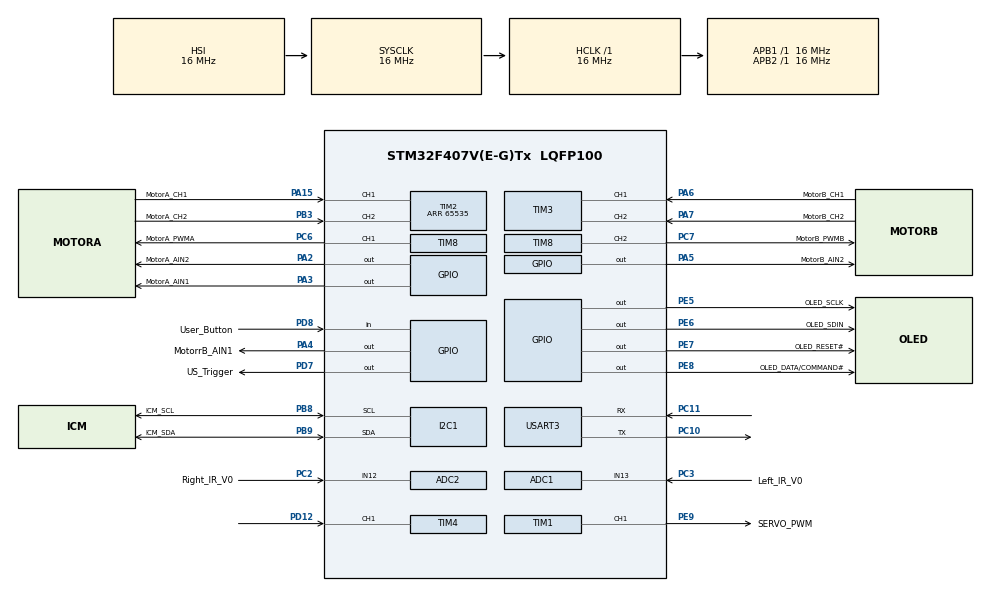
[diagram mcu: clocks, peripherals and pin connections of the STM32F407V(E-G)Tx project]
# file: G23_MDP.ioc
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ADC1.Channel-0\#ChannelRegularConversion=ADC_CHANNEL_13
ADC1.ContinuousConvMode=ENABLE
ADC1.NbrOfConversion=1
ADC1.NbrOfConversionFlag=1
ADC1.Rank-0\#ChannelRegularConversion=1
ADC1.Resolution=ADC_RESOLUTION_12B
ADC1.SamplingTime-0\#ChannelRegularConversion=ADC_SAMPLETIME_3CYCLES
ADC1.ScanConvMode=DISABLE
ADC1.master=1
ADC2.Channel-1\#ChannelRegularConversion=ADC_CHANNEL_12
ADC2.NbrOfConversionFlag=1
ADC2.Rank-1\#ChannelRegularConversion=1
ADC2.SamplingTime-1\#ChannelRegularConversion=ADC_SAMPLETIME_3CYCLES
I2C1.I2C_Mode=I2C_Fast
I2C1.NoStretchMode=I2C_NOSTRETCH_DISABLE
Mcu.Family=STM32F4
Mcu.Name=STM32F407V(E-G)Tx
Mcu.Package=LQFP100
NVIC.ADC_IRQn=true\:0\:0\:false\:false\:true\:true\:true\:true
NVIC.PriorityGroup=NVIC_PRIORITYGROUP_4
NVIC.TIM1_CC_IRQn=true\:0\:0\:false\:false\:true\:true\:true\:true
NVIC.TIM4_IRQn=true\:0\:0\:false\:false\:true\:true\:true\:true
NVIC.TIM7_IRQn=true\:0\:0\:false\:false\:true\:true\:true\:true
NVIC.USART3_IRQn=true\:0\:0\:false\:false\:true\:true\:true\:true
PA13.Signal=SYS_JTMS-SWDIO
PA14.Signal=SYS_JTCK-SWCLK
PA15.GPIO_Label=MotorA_CH1
PA15.Signal=S_TIM2_CH1_ETR
PA2.GPIO_Label=MotorA_AIN2
PA2.Signal=GPIO_Output
PA3.GPIO_Label=MotorA_AIN1
PA3.Signal=GPIO_Output
PA4.GPIO_Label=MotorrB_AIN1
PA4.Signal=GPIO_Output
PA5.GPIO_Label=MotorB_AIN2
PA5.Signal=GPIO_Output
PA6.GPIO_Label=MotorB_CH1
PA6.Signal=S_TIM3_CH1
PA7.GPIO_Label=MotorB_CH2
PA7.Signal=S_TIM3_CH2
PB3.GPIO_Label=MotorA_CH2
PB3.Signal=S_TIM2_CH2
PB8.GPIO_Label=ICM_SCL
PB8.Mode=I2C
PB8.Signal=I2C1_SCL
PB9.GPIO_Label=ICM_SDA
PB9.Mode=I2C
PB9.Signal=I2C1_SDA
PC10.Mode=Asynchronous
PC10.Signal=USART3_TX
PC11.Mode=Asynchronous
PC11.Signal=USART3_RX
PC2.GPIO_Label=Right_IR_V0
PC2.Signal=ADCx_IN12
PC3.GPIO_Label=Left_IR_V0
PC3.Signal=ADCx_IN13
PC6.GPIO_Label=MotorA_PWMA
PC6.Signal=S_TIM8_CH1
PC7.GPIO_Label=MotorB_PWMB
PC7.Signal=S_TIM8_CH2
PD12.Signal=S_TIM4_CH1
PD7.GPIO_Label=US_Trigger
PD7.Signal=GPIO_Output
PD8.GPIO_Label=User_Button
PD8.GPIO_PuPd=GPIO_PULLUP
PD8.Signal=GPIO_Input
PE5.GPIO_Label=OLED_SCLK
PE5.Signal=GPIO_Output
PE6.GPIO_Label=OLED_SDIN
PE6.Signal=GPIO_Output
PE7.GPIO_Label=OLED_RESET\#
PE7.Signal=GPIO_Output
PE8.GPIO_Label=OLED_DATA/COMMAND\#
PE8.Signal=GPIO_Output
PE9.GPIO_Label=SERVO_PWM
PE9.Signal=S_TIM1_CH1
ProjectManager.HeapSize=0x200
ProjectManager.StackSize=0x400
ProjectManager.TargetToolchain=STM32CubeIDE
RCC.AHBFreq_Value=16000000
RCC.APB1Freq_Value=16000000
RCC.APB2Freq_Value=16000000
RCC.APB2TimFreq_Value=16000000
RCC.CortexFreq_Value=16000000
RCC.HSE_VALUE=25000000
RCC.HSI_VALUE=16000000
RCC.LSE_VALUE=32768
RCC.SYSCLKFreq_VALUE=16000000
RCC.VCOOutputFreq_Value=192000000
SH.ADCx_IN12.0=ADC2_IN12,IN12
SH.ADCx_IN13.0=ADC1_IN13,IN13
SH.S_TIM1_CH1.0=TIM1_CH1,PWM Generation1 CH1
SH.S_TIM2_CH1_ETR.0=TIM2_CH1,Encoder_Interface
SH.S_TIM2_CH2.0=TIM2_CH2,Encoder_Interface
SH.S_TIM3_CH1.0=TIM3_CH1,Encoder_Interface
SH.S_TIM3_CH2.0=TIM3_CH2,Encoder_Interface
SH.S_TIM4_CH1.0=TIM4_CH1,Input_Capture1_from_TI1
SH.S_TIM8_CH1.0=TIM8_CH1,PWM Generation1 CH1
SH.S_TIM8_CH2.0=TIM8_CH2,PWM Generation2 CH2
TIM1.Channel-PWM\ Generation1\ CH1=TIM_CHANNEL_1
TIM1.CounterMode=TIM_COUNTERMODE_UP
TIM1.OCMode_PWM-PWM\ Generation1\ CH1=TIM_OCMODE_PWM1
TIM1.Period=64000-1
TIM1.Prescaler=5-1
TIM2.EncoderMode=TIM_ENCODERMODE_TI12
TIM2.IC1Polarity=TIM_ICPOLARITY_RISING
TIM2.IC2Polarity=TIM_ICPOLARITY_RISING
TIM2.Period=65535
TIM3.EncoderMode=TIM_ENCODERMODE_TI12
TIM3.IC1Filter=0
TIM3.IC1Polarity=TIM_ICPOLARITY_RISING
TIM3.IC2Filter=0
TIM3.IC2Polarity=TIM_ICPOLARITY_RISING
TIM4.Channel-Input_Capture1_from_TI1=TIM_CHANNEL_1
TIM4.Period=65536-1
TIM4.Prescaler=16-1
TIM6.Period=65536-1
TIM6.Prescaler=16-1
TIM7.Period=16000-1
TIM7.Prescaler=2-1
TIM8.Channel-PWM\ Generation1\ CH1=TIM_CHANNEL_1
TIM8.Channel-PWM\ Generation2\ CH2=TIM_CHANNEL_2
TIM8.Period=7200-1
USART3.VirtualMode=VM_ASYNC
VP_TIM1_VS_ClockSourceINT.Mode=Internal
VP_TIM4_VS_ClockSourceINT.Mode=Internal
VP_TIM6_VS_ClockSourceINT.Mode=Enable_Timer
VP_TIM7_VS_ClockSourceINT.Mode=Enable_Timer
VP_TIM8_VS_ClockSourceINT.Mode=Internal
board=custom

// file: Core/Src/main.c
/* USER CODE BEGIN Header */
/**
  ******************************************************************************
  * @file           : main.c
  * @brief          : Main program body
  ******************************************************************************
  * @attention
  *
  * Copyright (c) 2024 STMicroelectronics.
  * All rights reserved.
  *
  * This software is licensed under terms that can be found in the LICENSE file
  * in the root directory of this software component.
  * If no LICENSE file comes with this software, it is provided AS-IS.
  *
  ******************************************************************************
  */
/* USER CODE END Header */
#include <userbutton.h>
#include "main.h"

/* USER CODE BEGIN Includes */
#include "oled.h"
#include "userbutton.h"
#include "servomotor.h"
#include "sensorstuff.h"

/* USER CODE END Includes */

ADC_HandleTypeDef hadc1;
ADC_HandleTypeDef hadc2;

I2C_HandleTypeDef hi2c1;

TIM_HandleTypeDef htim1;
TIM_HandleTypeDef htim2;
TIM_HandleTypeDef htim3;
TIM_HandleTypeDef htim4;
TIM_HandleTypeDef htim6;
TIM_HandleTypeDef htim7;
TIM_HandleTypeDef htim8;

UART_HandleTypeDef huart3;

void SystemClock_Config(void);
static void MX_GPIO_Init(void);
static void MX_USART3_UART_Init(void);
static void MX_I2C1_Init(void);
static void MX_TIM8_Init(void);
static void MX_TIM2_Init(void);
static void MX_TIM3_Init(void);
static void MX_TIM1_Init(void);
static void MX_TIM4_Init(void);
static void MX_ADC1_Init(void);
static void MX_TIM6_Init(void);
static void MX_TIM7_Init(void);
static void MX_ADC2_Init(void);

int main(void)
{

  /* MCU Configuration--------------------------------------------------------*/

  /* Reset of all peripherals, Initializes the Flash interface and the Systick. */
  HAL_Init();

  /* USER CODE BEGIN Init */
  OLED_Init();
  /* USER CODE END Init */

  /* Configure the system clock */
  SystemClock_Config();

  /* Initialize all configured peripherals */
  MX_GPIO_Init();
  MX_USART3_UART_Init();
  MX_I2C1_Init();
  MX_TIM8_Init();
  MX_TIM2_Init();
  MX_TIM3_Init();
  MX_TIM1_Init();
  MX_TIM4_Init();
  MX_ADC1_Init();
  MX_TIM6_Init();
  MX_TIM7_Init();
  MX_ADC2_Init();

  /* Infinite loop */
  while (1)
  {

  }
}

void SystemClock_Config(void)
{
  RCC_OscInitTypeDef RCC_OscInitStruct = {0};
  RCC_ClkInitTypeDef RCC_ClkInitStruct = {0};

  /** Configure the main internal regulator output voltage
  */
  __HAL_RCC_PWR_CLK_ENABLE();
  __HAL_PWR_VOLTAGESCALING_CONFIG(PWR_REGULATOR_VOLTAGE_SCALE1);

  /** Initializes the RCC Oscillators according to the specified parameters
  * in the RCC_OscInitTypeDef structure.
  */
  RCC_OscInitStruct.OscillatorType = RCC_OSCILLATORTYPE_HSI;
  RCC_OscInitStruct.HSIState = RCC_HSI_ON;
  RCC_OscInitStruct.HSICalibrationValue = RCC_HSICALIBRATION_DEFAULT;
  RCC_OscInitStruct.PLL.PLLState = RCC_PLL_NONE;
  if (HAL_RCC_OscConfig(&RCC_OscInitStruct) != HAL_OK)
  {
    Error_Handler();
  }

  /** Initializes the CPU, AHB and APB buses clocks
  */
  RCC_ClkInitStruct.ClockType = RCC_CLOCKTYPE_HCLK|RCC_CLOCKTYPE_SYSCLK
                              |RCC_CLOCKTYPE_PCLK1|RCC_CLOCKTYPE_PCLK2;
  RCC_ClkInitStruct.SYSCLKSource = RCC_SYSCLKSOURCE_HSI;
  RCC_ClkInitStruct.AHBCLKDivider = RCC_SYSCLK_DIV1;
  RCC_ClkInitStruct.APB1CLKDivider = RCC_HCLK_DIV1;
  RCC_ClkInitStruct.APB2CLKDivider = RCC_HCLK_DIV1;

  if (HAL_RCC_ClockConfig(&RCC_ClkInitStruct, FLASH_LATENCY_0) != HAL_OK)
  {
    Error_Handler();
  }
}

static void MX_ADC1_Init(void)
{

  ADC_ChannelConfTypeDef sConfig = {0};

  /** Configure the global features of the ADC (Clock, Resolution, Data Alignment and number of conversion)
  */
  hadc1.Instance = ADC1;
  hadc1.Init.ClockPrescaler = ADC_CLOCK_SYNC_PCLK_DIV2;
  hadc1.Init.Resolution = ADC_RESOLUTION_12B;
  hadc1.Init.ScanConvMode = DISABLE;
  hadc1.Init.ContinuousConvMode = ENABLE;
  hadc1.Init.DiscontinuousConvMode = DISABLE;
  hadc1.Init.ExternalTrigConvEdge = ADC_EXTERNALTRIGCONVEDGE_NONE;
  hadc1.Init.ExternalTrigConv = ADC_SOFTWARE_START;
  hadc1.Init.DataAlign = ADC_DATAALIGN_RIGHT;
  hadc1.Init.NbrOfConversion = 1;
  hadc1.Init.DMAContinuousRequests = DISABLE;
  hadc1.Init.EOCSelection = ADC_EOC_SINGLE_CONV;
  if (HAL_ADC_Init(&hadc1) != HAL_OK)
  {
    Error_Handler();
  }

  /** Configure for the selected ADC regular channel its corresponding rank in the sequencer and its sample time.
  */
  sConfig.Channel = ADC_CHANNEL_13;
  sConfig.Rank = 1;
  sConfig.SamplingTime = ADC_SAMPLETIME_3CYCLES;
  if (HAL_ADC_ConfigChannel(&hadc1, &sConfig) != HAL_OK)
  {
    Error_Handler();
  }

}

static void MX_ADC2_Init(void)
{

  ADC_ChannelConfTypeDef sConfig = {0};

  /** Configure the global features of the ADC (Clock, Resolution, Data Alignment and number of conversion)
  */
  hadc2.Instance = ADC2;
  hadc2.Init.ClockPrescaler = ADC_CLOCK_SYNC_PCLK_DIV2;
  hadc2.Init.Resolution = ADC_RESOLUTION_12B;
  hadc2.Init.ScanConvMode = DISABLE;
  hadc2.Init.ContinuousConvMode = DISABLE;
  hadc2.Init.DiscontinuousConvMode = DISABLE;
  hadc2.Init.ExternalTrigConvEdge = ADC_EXTERNALTRIGCONVEDGE_NONE;
  hadc2.Init.ExternalTrigConv = ADC_SOFTWARE_START;
  hadc2.Init.DataAlign = ADC_DATAALIGN_RIGHT;
  hadc2.Init.NbrOfConversion = 1;
  hadc2.Init.DMAContinuousRequests = DISABLE;
  hadc2.Init.EOCSelection = ADC_EOC_SINGLE_CONV;
  if (HAL_ADC_Init(&hadc2) != HAL_OK)
  {
    Error_Handler();
  }

  /** Configure for the selected ADC regular channel its corresponding rank in the sequencer and its sample time.
  */
  sConfig.Channel = ADC_CHANNEL_12;
  sConfig.Rank = 1;
  sConfig.SamplingTime = ADC_SAMPLETIME_3CYCLES;
  if (HAL_ADC_ConfigChannel(&hadc2, &sConfig) != HAL_OK)
  {
    Error_Handler();
  }

}

static void MX_I2C1_Init(void)
{

  hi2c1.Instance = I2C1;
  hi2c1.Init.ClockSpeed = 400000;
  hi2c1.Init.DutyCycle = I2C_DUTYCYCLE_2;
  hi2c1.Init.OwnAddress1 = 0;
  hi2c1.Init.AddressingMode = I2C_ADDRESSINGMODE_7BIT;
  hi2c1.Init.DualAddressMode = I2C_DUALADDRESS_DISABLE;
  hi2c1.Init.OwnAddress2 = 0;
  hi2c1.Init.GeneralCallMode = I2C_GENERALCALL_DISABLE;
  hi2c1.Init.NoStretchMode = I2C_NOSTRETCH_DISABLE;
  if (HAL_I2C_Init(&hi2c1) != HAL_OK)
  {
    Error_Handler();
  }

}

static void MX_TIM1_Init(void)
{

  TIM_ClockConfigTypeDef sClockSourceConfig = {0};
  TIM_MasterConfigTypeDef sMasterConfig = {0};
  TIM_OC_InitTypeDef sConfigOC = {0};
  TIM_BreakDeadTimeConfigTypeDef sBreakDeadTimeConfig = {0};

  htim1.Instance = TIM1;
  htim1.Init.Prescaler = 5-1;
  htim1.Init.CounterMode = TIM_COUNTERMODE_UP;
  htim1.Init.Period = 64000-1;
  htim1.Init.ClockDivision = TIM_CLOCKDIVISION_DIV1;
  htim1.Init.RepetitionCounter = 0;
  htim1.Init.AutoReloadPreload = TIM_AUTORELOAD_PRELOAD_DISABLE;
  if (HAL_TIM_Base_Init(&htim1) != HAL_OK)
  {
    Error_Handler();
  }
  sClockSourceConfig.ClockSource = TIM_CLOCKSOURCE_INTERNAL;
  if (HAL_TIM_ConfigClockSource(&htim1, &sClockSourceConfig) != HAL_OK)
  {
    Error_Handler();
  }
  if (HAL_TIM_PWM_Init(&htim1) != HAL_OK)
  {
    Error_Handler();
  }
  sMasterConfig.MasterOutputTrigger = TIM_TRGO_RESET;
  sMasterConfig.MasterSlaveMode = TIM_MASTERSLAVEMODE_DISABLE;
  if (HAL_TIMEx_MasterConfigSynchronization(&htim1, &sMasterConfig) != HAL_OK)
  {
    Error_Handler();
  }
  sConfigOC.OCMode = TIM_OCMODE_PWM1;
  sConfigOC.Pulse = 0;
  sConfigOC.OCPolarity = TIM_OCPOLARITY_HIGH;
  sConfigOC.OCNPolarity = TIM_OCNPOLARITY_HIGH;
  sConfigOC.OCFastMode = TIM_OCFAST_DISABLE;
  sConfigOC.OCIdleState = TIM_OCIDLESTATE_RESET;
  sConfigOC.OCNIdleState = TIM_OCNIDLESTATE_RESET;
  if (HAL_TIM_PWM_ConfigChannel(&htim1, &sConfigOC, TIM_CHANNEL_1) != HAL_OK)
  {
    Error_Handler();
  }
  sBreakDeadTimeConfig.OffStateRunMode = TIM_OSSR_DISABLE;
  sBreakDeadTimeConfig.OffStateIDLEMode = TIM_OSSI_DISABLE;
  sBreakDeadTimeConfig.LockLevel = TIM_LOCKLEVEL_OFF;
  sBreakDeadTimeConfig.DeadTime = 0;
  sBreakDeadTimeConfig.BreakState = TIM_BREAK_DISABLE;
  sBreakDeadTimeConfig.BreakPolarity = TIM_BREAKPOLARITY_HIGH;
  sBreakDeadTimeConfig.AutomaticOutput = TIM_AUTOMATICOUTPUT_DISABLE;
  if (HAL_TIMEx_ConfigBreakDeadTime(&htim1, &sBreakDeadTimeConfig) != HAL_OK)
  {
    Error_Handler();
  }
  HAL_TIM_MspPostInit(&htim1);

}

static void MX_TIM2_Init(void)
{

  TIM_Encoder_InitTypeDef sConfig = {0};
  TIM_MasterConfigTypeDef sMasterConfig = {0};

  htim2.Instance = TIM2;
  htim2.Init.Prescaler = 0;
  htim2.Init.CounterMode = TIM_COUNTERMODE_UP;
  htim2.Init.Period = 65535;
  htim2.Init.ClockDivision = TIM_CLOCKDIVISION_DIV1;
  htim2.Init.AutoReloadPreload = TIM_AUTORELOAD_PRELOAD_DISABLE;
  sConfig.EncoderMode = TIM_ENCODERMODE_TI12;
  sConfig.IC1Polarity = TIM_ICPOLARITY_RISING;
  sConfig.IC1Selection = TIM_ICSELECTION_DIRECTTI;
  sConfig.IC1Prescaler = TIM_ICPSC_DIV1;
  sConfig.IC1Filter = 0;
  sConfig.IC2Polarity = TIM_ICPOLARITY_RISING;
  sConfig.IC2Selection = TIM_ICSELECTION_DIRECTTI;
  sConfig.IC2Prescaler = TIM_ICPSC_DIV1;
  sConfig.IC2Filter = 0;
  if (HAL_TIM_Encoder_Init(&htim2, &sConfig) != HAL_OK)
  {
    Error_Handler();
  }
  sMasterConfig.MasterOutputTrigger = TIM_TRGO_RESET;
  sMasterConfig.MasterSlaveMode = TIM_MASTERSLAVEMODE_DISABLE;
  if (HAL_TIMEx_MasterConfigSynchronization(&htim2, &sMasterConfig) != HAL_OK)
  {
    Error_Handler();
  }

}

static void MX_TIM3_Init(void)
{

  TIM_Encoder_InitTypeDef sConfig = {0};
  TIM_MasterConfigTypeDef sMasterConfig = {0};

  htim3.Instance = TIM3;
  htim3.Init.Prescaler = 0;
  htim3.Init.CounterMode = TIM_COUNTERMODE_UP;
  htim3.Init.Period = 65535;
  htim3.Init.ClockDivision = TIM_CLOCKDIVISION_DIV1;
  htim3.Init.AutoReloadPreload = TIM_AUTORELOAD_PRELOAD_DISABLE;
  sConfig.EncoderMode = TIM_ENCODERMODE_TI12;
  sConfig.IC1Polarity = TIM_ICPOLARITY_RISING;
  sConfig.IC1Selection = TIM_ICSELECTION_DIRECTTI;
  sConfig.IC1Prescaler = TIM_ICPSC_DIV1;
  sConfig.IC1Filter = 0;
  sConfig.IC2Polarity = TIM_ICPOLARITY_RISING;
  sConfig.IC2Selection = TIM_ICSELECTION_DIRECTTI;
  sConfig.IC2Prescaler = TIM_ICPSC_DIV1;
  sConfig.IC2Filter = 0;
  if (HAL_TIM_Encoder_Init(&htim3, &sConfig) != HAL_OK)
  {
    Error_Handler();
  }
  sMasterConfig.MasterOutputTrigger = TIM_TRGO_RESET;
  sMasterConfig.MasterSlaveMode = TIM_MASTERSLAVEMODE_DISABLE;
  if (HAL_TIMEx_MasterConfigSynchronization(&htim3, &sMasterConfig) != HAL_OK)
  {
    Error_Handler();
  }

}

static void MX_TIM4_Init(void)
{

  TIM_ClockConfigTypeDef sClockSourceConfig = {0};
  TIM_MasterConfigTypeDef sMasterConfig = {0};
  TIM_IC_InitTypeDef sConfigIC = {0};

  htim4.Instance = TIM4;
  htim4.Init.Prescaler = 16-1;
  htim4.Init.CounterMode = TIM_COUNTERMODE_UP;
  htim4.Init.Period = 65536-1;
  htim4.Init.ClockDivision = TIM_CLOCKDIVISION_DIV1;
  htim4.Init.AutoReloadPreload = TIM_AUTORELOAD_PRELOAD_DISABLE;
  if (HAL_TIM_Base_Init(&htim4) != HAL_OK)
  {
    Error_Handler();
  }
  sClockSourceConfig.ClockSource = TIM_CLOCKSOURCE_INTERNAL;
  if (HAL_TIM_ConfigClockSource(&htim4, &sClockSourceConfig) != HAL_OK)
  {
    Error_Handler();
  }
  if (HAL_TIM_IC_Init(&htim4) != HAL_OK)
  {
    Error_Handler();
  }
  sMasterConfig.MasterOutputTrigger = TIM_TRGO_RESET;
  sMasterConfig.MasterSlaveMode = TIM_MASTERSLAVEMODE_DISABLE;
  if (HAL_TIMEx_MasterConfigSynchronization(&htim4, &sMasterConfig) != HAL_OK)
  {
    Error_Handler();
  }
  sConfigIC.ICPolarity = TIM_INPUTCHANNELPOLARITY_RISING;
  sConfigIC.ICSelection = TIM_ICSELECTION_DIRECTTI;
  sConfigIC.ICPrescaler = TIM_ICPSC_DIV1;
  sConfigIC.ICFilter = 0;
  if (HAL_TIM_IC_ConfigChannel(&htim4, &sConfigIC, TIM_CHANNEL_1) != HAL_OK)
  {
    Error_Handler();
  }

}

static void MX_TIM6_Init(void)
{

  TIM_MasterConfigTypeDef sMasterConfig = {0};

  htim6.Instance = TIM6;
  htim6.Init.Prescaler = 16-1;
  htim6.Init.CounterMode = TIM_COUNTERMODE_UP;
  htim6.Init.Period = 65536-1;
  htim6.Init.AutoReloadPreload = TIM_AUTORELOAD_PRELOAD_DISABLE;
  if (HAL_TIM_Base_Init(&htim6) != HAL_OK)
  {
    Error_Handler();
  }
  sMasterConfig.MasterOutputTrigger = TIM_TRGO_RESET;
  sMasterConfig.MasterSlaveMode = TIM_MASTERSLAVEMODE_DISABLE;
  if (HAL_TIMEx_MasterConfigSynchronization(&htim6, &sMasterConfig) != HAL_OK)
  {
    Error_Handler();
  }

}

static void MX_TIM7_Init(void)
{

  TIM_MasterConfigTypeDef sMasterConfig = {0};

  htim7.Instance = TIM7;
  htim7.Init.Prescaler = 2-1;
  htim7.Init.CounterMode = TIM_COUNTERMODE_UP;
  htim7.Init.Period = 16000-1;
  htim7.Init.AutoReloadPreload = TIM_AUTORELOAD_PRELOAD_DISABLE;
  if (HAL_TIM_Base_Init(&htim7) != HAL_OK)
  {
    Error_Handler();
  }
  sMasterConfig.MasterOutputTrigger = TIM_TRGO_RESET;
  sMasterConfig.MasterSlaveMode = TIM_MASTERSLAVEMODE_DISABLE;
  if (HAL_TIMEx_MasterConfigSynchronization(&htim7, &sMasterConfig) != HAL_OK)
  {
    Error_Handler();
  }

}

static void MX_TIM8_Init(void)
{

  TIM_ClockConfigTypeDef sClockSourceConfig = {0};
  TIM_MasterConfigTypeDef sMasterConfig = {0};
  TIM_OC_InitTypeDef sConfigOC = {0};
  TIM_BreakDeadTimeConfigTypeDef sBreakDeadTimeConfig = {0};

  htim8.Instance = TIM8;
  htim8.Init.Prescaler = 0;
  htim8.Init.CounterMode = TIM_COUNTERMODE_UP;
  htim8.Init.Period = 7200-1;
  htim8.Init.ClockDivision = TIM_CLOCKDIVISION_DIV1;
  htim8.Init.RepetitionCounter = 0;
  htim8.Init.AutoReloadPreload = TIM_AUTORELOAD_PRELOAD_DISABLE;
  if (HAL_TIM_Base_Init(&htim8) != HAL_OK)
  {
    Error_Handler();
  }
  sClockSourceConfig.ClockSource = TIM_CLOCKSOURCE_INTERNAL;
  if (HAL_TIM_ConfigClockSource(&htim8, &sClockSourceConfig) != HAL_OK)
  {
    Error_Handler();
  }
  if (HAL_TIM_PWM_Init(&htim8) != HAL_OK)
  {
    Error_Handler();
  }
  sMasterConfig.MasterOutputTrigger = TIM_TRGO_RESET;
  sMasterConfig.MasterSlaveMode = TIM_MASTERSLAVEMODE_DISABLE;
  if (HAL_TIMEx_MasterConfigSynchronization(&htim8, &sMasterConfig) != HAL_OK)
  {
    Error_Handler();
  }
  sConfigOC.OCMode = TIM_OCMODE_PWM1;
  sConfigOC.Pulse = 0;
  sConfigOC.OCPolarity = TIM_OCPOLARITY_HIGH;
  sConfigOC.OCNPolarity = TIM_OCNPOLARITY_HIGH;
  sConfigOC.OCFastMode = TIM_OCFAST_DISABLE;
  sConfigOC.OCIdleState = TIM_OCIDLESTATE_RESET;
  sConfigOC.OCNIdleState = TIM_OCNIDLESTATE_RESET;
  if (HAL_TIM_PWM_ConfigChannel(&htim8, &sConfigOC, TIM_CHANNEL_1) != HAL_OK)
  {
    Error_Handler();
  }
  if (HAL_TIM_PWM_ConfigChannel(&htim8, &sConfigOC, TIM_CHANNEL_2) != HAL_OK)
  {
    Error_Handler();
  }
  sBreakDeadTimeConfig.OffStateRunMode = TIM_OSSR_DISABLE;
  sBreakDeadTimeConfig.OffStateIDLEMode = TIM_OSSI_DISABLE;
  sBreakDeadTimeConfig.LockLevel = TIM_LOCKLEVEL_OFF;
  sBreakDeadTimeConfig.DeadTime = 0;
  sBreakDeadTimeConfig.BreakState = TIM_BREAK_DISABLE;
  sBreakDeadTimeConfig.BreakPolarity = TIM_BREAKPOLARITY_HIGH;
  sBreakDeadTimeConfig.AutomaticOutput = TIM_AUTOMATICOUTPUT_DISABLE;
  if (HAL_TIMEx_ConfigBreakDeadTime(&htim8, &sBreakDeadTimeConfig) != HAL_OK)
  {
    Error_Handler();
  }
  HAL_TIM_MspPostInit(&htim8);

}

static void MX_USART3_UART_Init(void)
{

  huart3.Instance = USART3;
  huart3.Init.BaudRate = 115200;
  huart3.Init.WordLength = UART_WORDLENGTH_8B;
  huart3.Init.StopBits = UART_STOPBITS_1;
  huart3.Init.Parity = UART_PARITY_NONE;
  huart3.Init.Mode = UART_MODE_TX_RX;
  huart3.Init.HwFlowCtl = UART_HWCONTROL_NONE;
  huart3.Init.OverSampling = UART_OVERSAMPLING_16;
  if (HAL_UART_Init(&huart3) != HAL_OK)
  {
    Error_Handler();
  }

}

static void MX_GPIO_Init(void)
{
  GPIO_InitTypeDef GPIO_InitStruct = {0};

  /* GPIO Ports Clock Enable */
  __HAL_RCC_GPIOE_CLK_ENABLE();
  __HAL_RCC_GPIOC_CLK_ENABLE();
  __HAL_RCC_GPIOA_CLK_ENABLE();
  __HAL_RCC_GPIOD_CLK_ENABLE();
  __HAL_RCC_GPIOB_CLK_ENABLE();

  /*Configure GPIO pin Output Level */
  HAL_GPIO_WritePin(GPIOE, OLED_SCLK_Pin|OLED_SDIN_Pin|OLED_RESET__Pin|OLED_DATA_COMMAND__Pin, GPIO_PIN_RESET);

  /*Configure GPIO pin Output Level */
  HAL_GPIO_WritePin(GPIOA, MotorA_AIN2_Pin|MotorA_AIN1_Pin|MotorrB_AIN1_Pin|MotorB_AIN2_Pin, GPIO_PIN_RESET);

  /*Configure GPIO pin Output Level */
  HAL_GPIO_WritePin(US_Trigger_GPIO_Port, US_Trigger_Pin, GPIO_PIN_RESET);

  /*Configure GPIO pins : OLED_SCLK_Pin OLED_SDIN_Pin OLED_RESET__Pin OLED_DATA_COMMAND__Pin */
  GPIO_InitStruct.Pin = OLED_SCLK_Pin|OLED_SDIN_Pin|OLED_RESET__Pin|OLED_DATA_COMMAND__Pin;
  GPIO_InitStruct.Mode = GPIO_MODE_OUTPUT_PP;
  GPIO_InitStruct.Pull = GPIO_NOPULL;
  GPIO_InitStruct.Speed = GPIO_SPEED_FREQ_LOW;
  HAL_GPIO_Init(GPIOE, &GPIO_InitStruct);

  /*Configure GPIO pins : MotorA_AIN2_Pin MotorA_AIN1_Pin MotorrB_AIN1_Pin MotorB_AIN2_Pin */
  GPIO_InitStruct.Pin = MotorA_AIN2_Pin|MotorA_AIN1_Pin|MotorrB_AIN1_Pin|MotorB_AIN2_Pin;
  GPIO_InitStruct.Mode = GPIO_MODE_OUTPUT_PP;
  GPIO_InitStruct.Pull = GPIO_NOPULL;
  GPIO_InitStruct.Speed = GPIO_SPEED_FREQ_LOW;
  HAL_GPIO_Init(GPIOA, &GPIO_InitStruct);

  /*Configure GPIO pin : User_Button_Pin */
  GPIO_InitStruct.Pin = User_Button_Pin;
  GPIO_InitStruct.Mode = GPIO_MODE_INPUT;
  GPIO_InitStruct.Pull = GPIO_PULLUP;
  HAL_GPIO_Init(User_Button_GPIO_Port, &GPIO_InitStruct);

  /*Configure GPIO pin : US_Trigger_Pin */
  GPIO_InitStruct.Pin = US_Trigger_Pin;
  GPIO_InitStruct.Mode = GPIO_MODE_OUTPUT_PP;
  GPIO_InitStruct.Pull = GPIO_NOPULL;
  GPIO_InitStruct.Speed = GPIO_SPEED_FREQ_LOW;
  HAL_GPIO_Init(US_Trigger_GPIO_Port, &GPIO_InitStruct);

}

void Error_Handler(void)
{
  __disable_irq();
  while (1)
  {
  }
}
